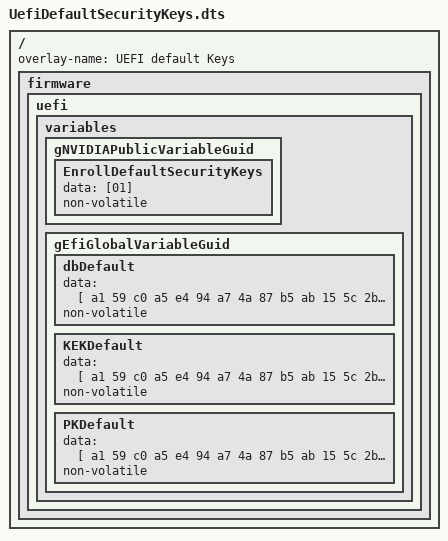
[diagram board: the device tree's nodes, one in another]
/dts-v1/;
/plugin/;
/ {
    overlay-name = "UEFI default Keys";
    fragment@0 {
        target-path = "/";
        board_config {
            sw-modules = "uefi";
        };
        __overlay__ {
            firmware {
                uefi {
                    variables {
                        gNVIDIAPublicVariableGuid {
                            EnrollDefaultSecurityKeys {
                                data = [01];
                                non-volatile;
                            };
                        };
                        gEfiGlobalVariableGuid {
                            dbDefault {
                                data = [
 a1 59 c0 a5 e4 94 a7 4a 87 b5 ab 15 5c 2b f0 72
 45 05 00 00 00 00 00 00 29 05 00 00 67 45 23 01
 ab 89 ef cd 01 23 45 67 89 ab cd ef 30 82 05 15
 30 82 02 fd a0 03 02 01 02 02 14 57 7c a4 0c 8e
 89 bd 30 b7 32 72 16 68 e7 be 2f f2 ab 0b 0f 30
 0d 06 09 2a 86 48 86 f7 0d 01 01 0b 05 00 30 1a
 31 18 30 16 06 03 55 04 03 0c 0f 51 55 41 4c 47
 4f 20 44 42 20 75 65 66 69 31 30 1e 17 0d 32 36
 30 31 30 38 30 36 33 39 30 33 5a 17 0d 33 36 30
 31 30 36 30 36 33 39 30 33 5a 30 1a 31 18 30 16
 06 03 55 04 03 0c 0f 51 55 41 4c 47 4f 20 44 42
 20 75 65 66 69 31 30 82 02 22 30 0d 06 09 2a 86
 48 86 f7 0d 01 01 01 05 00 03 82 02 0f 00 30 82
 02 0a 02 82 02 01 00 f1 f5 b0 6b da cb fa 9c dc
 51 bf 3c e8 96 7a aa e0 8d fe e7 57 ea 79 83 bf
 37 cf ec 4f c1 ca 91 08 57 de ee ae 32 b4 49 be
 80 4b 5f db 68 19 c5 31 b3 a8 4c 23 97 56 7a 4b
 98 7a 26 27 4c 02 b4 20 4f 98 23 fa fa 7a f4 a1
 a3 08 e1 de 35 e8 19 8c 83 12 7e c7 fd 82 a0 79
 41 15 76 a1 21 22 38 b6 3b cc 27 88 2b c1 5f d1
 13 4b ca 03 be d0 67 bc 83 cc a6 5e 26 17 4b f2
 2d c8 c3 53 eb 8b 39 2c fe 3e e5 c0 f3 ce b0 f0
 c8 42 19 b6 09 c5 dc 21 05 1d 9d ee f2 e1 aa 7b
 8f 8e 98 90 2d fb 41 a7 9d 07 ff 31 95 4d d4 59
 a0 89 cf 33 b9 e5 8b 2d 5a 9e 0b 37 46 fa d1 b4
 91 ee 3b ef 3b 04 1c 17 5c f0 cd ad fb 23 60 f5
 47 ea 4c e0 30 f0 1c 8d 01 dd b0 c8 dc 02 fb a4
 50 35 06 72 38 a9 f7 bb 68 82 79 c4 c4 1d 00 c4
 d0 ac 75 34 76 de ad e9 07 e6 63 b0 80 49 25 45
 5a 03 f1 26 50 74 1b a5 f0 47 7c 84 31 51 ca 90
 d0 08 7d 96 61 42 84 71 b9 76 66 a3 2f c1 0b 34
 db 1e cc 6e 17 14 3e 84 a5 27 d4 48 cf 52 a0 7f
 3d 07 32 77 4f 6b 28 13 de e0 b1 71 18 b0 09 e1
 f6 d8 32 9b 73 60 66 08 44 c5 6c b6 1d 63 9e ef
 3e 1d 0a ab ac 57 a1 90 a8 06 39 34 5b 7d 18 b5
 90 cb 73 ee 1b 26 cc da c4 4e 38 58 19 65 67 e7
 fe f7 00 6e 80 ae 2d 9a 71 09 c9 16 24 57 fa d9
 09 03 a5 6a 39 31 06 9d 1a 99 71 f0 d7 cf a6 e5
 40 db 4d 19 a6 19 f0 c3 cf 93 c6 64 48 24 1b fe
 08 09 5f ef a9 ed 24 61 57 23 44 8b 40 c1 77 b2
 a5 e9 f4 8f c0 b0 25 ac d1 88 3e 7b 69 cb 20 58
 28 21 ac 9d 23 d4 c9 fe b1 54 37 ca 64 e2 d2 32
 ee 4f db e2 6b 7d 11 4e 2a 73 9f ec e6 0f 3a 47
 d9 01 1d 2f d1 b1 e6 dd 9c 31 bf fb 8b 17 b7 47
 b0 a1 af 93 9f 8c 8c 11 d9 73 b4 ca bf a0 f9 74
 92 a9 ac 74 d1 19 49 02 03 01 00 01 a3 53 30 51
 30 1d 06 03 55 1d 0e 04 16 04 14 e0 ea da e5 1f
 ef 96 45 55 63 8d 63 1f a7 40 92 a4 90 94 ac 30
 1f 06 03 55 1d 23 04 18 30 16 80 14 e0 ea da e5
 1f ef 96 45 55 63 8d 63 1f a7 40 92 a4 90 94 ac
 30 0f 06 03 55 1d 13 01 01 ff 04 05 30 03 01 01
 ff 30 0d 06 09 2a 86 48 86 f7 0d 01 01 0b 05 00
 03 82 02 01 00 f1 82 a8 df 2c bc 40 50 fe f3 ed
 9f b2 b2 c8 a1 c4 e5 f3 c6 2f 0c 60 60 49 83 79
 34 a2 01 99 ae fa 3b f5 ab 24 4e 55 43 08 7c f1
 bb 25 2d 77 d7 02 b8 38 c4 85 a0 63 84 e5 9c bf
 2c 3c a6 82 aa b4 b6 b5 03 35 e7 f5 dc 87 76 52
 d4 4f 77 0d f8 a0 3c d9 5a c2 88 1c be a5 cf 2f
 7c 34 01 b9 dc 08 6e b3 3a 3c 32 1e b3 6f 31 a5
 1d 24 c4 02 b0 2b 0f 6f a1 45 33 6e 7e 20 67 3d
 82 2f 06 3a 1b 28 c0 11 c6 e7 82 b3 02 cc a6 69
 53 5f ef 82 a3 45 af d0 0c 04 c6 0b cc 7c 2e 5f
 8b 82 33 a8 d4 58 d7 2f 3d 99 3f d8 88 91 78 53
 f2 56 60 23 27 56 fe ee 5b ca b9 31 d0 ba ab 9d
 eb c8 46 71 56 ff 83 1d d2 1b de 78 08 ef c4 e5
 b3 33 c5 f3 88 10 d9 30 b6 ed ee ae 59 f0 6a e0
 da 8a be 82 67 b1 86 c4 fe cd 1b 80 3f 83 a1 67
 e0 af ec 8e 4c ed 7b db 49 9e f4 b2 6f 05 90 03
 87 eb 99 25 10 50 95 e8 69 34 0d 62 ee aa 4c 24
 bc f2 ef 3d 57 76 b2 b9 b7 8a 82 6f f5 fe ac c6
 5e b2 c1 f5 09 f8 95 d3 b3 5e f6 da a7 56 cb 78
 10 e4 c3 2f 3d 96 52 43 3f e9 c3 24 0c 40 a6 71
 2a 06 31 c6 2e f6 08 b5 49 7b 1e 1a e0 06 d0 df
 26 30 cf 27 14 bc ea ad 3c 19 84 7a 6f 2e d6 92
 8c 41 90 8c 05 14 bc fc 24 76 f1 c0 96 26 50 be
 1d 74 a9 da ef 7e f2 db 8c 6d eb 7a bc ba 94 86
 f0 b8 a0 26 79 bf 70 bb 86 2a ea 43 56 2a 07 b5
 42 f9 e9 46 35 95 75 dc a2 eb a9 11 c1 f6 59 a2
 77 6e d3 3f 97 fc 46 c3 0b 03 6f 0e 64 b3 9a 2b
 8e 71 ca 34 f3 61 be f4 f6 86 78 5a 9e fa d6 9f
 16 68 a5 ce e8 30 7c db f3 58 96 a6 96 96 92 6d
 13 7b 58 40 af 14 a9 ac d3 d1 9d 21 34 1d b8 f7
 f9 3f 2a 6c e9 fb b7 3b 1d 86 dd c2 82 ce 2d 55
 b5 ce 28 2f d1 b9 a0 ef d6 52 3d e5 94 92 da 01
 6e 58 a5 64 e3 a1 59 c0 a5 e4 94 a7 4a 87 b5 ab
 15 5c 2b f0 72 45 05 00 00 00 00 00 00 29 05 00
 00 67 45 23 01 ab 89 ef cd 01 23 45 67 89 ab cd
 ef 30 82 05 15 30 82 02 fd a0 03 02 01 02 02 14
 2d 39 bd b9 61 43 fa 52 8c 0d 6c fe 65 6d 98 f5
 7c 57 fe 47 30 0d 06 09 2a 86 48 86 f7 0d 01 01
 0b 05 00 30 1a 31 18 30 16 06 03 55 04 03 0c 0f
 51 55 41 4c 47 4f 20 44 42 20 75 65 66 69 32 30
 1e 17 0d 32 36 30 31 30 38 30 36 33 39 30 33 5a
 17 0d 33 36 30 31 30 36 30 36 33 39 30 33 5a 30
 1a 31 18 30 16 06 03 55 04 03 0c 0f 51 55 41 4c
 47 4f 20 44 42 20 75 65 66 69 32 30 82 02 22 30
 0d 06 09 2a 86 48 86 f7 0d 01 01 01 05 00 03 82
 02 0f 00 30 82 02 0a 02 82 02 01 00 a6 04 c8 e1
 49 a4 44 9b ba 8c cd 31 cc 4d 05 40 37 dc ca 71
 2c 27 bc b2 71 70 b4 ad cd 0e e7 bd 8c a1 3b 45
 c3 e0 ee 68 19 a1 71 12 0f e3 35 de b7 71 a4 10
 f1 b4 d7 7e 1e 21 16 a6 bf ff a9 d3 33 97 c6 3b
 c9 c3 2e 2a 65 18 b4 9c 8b 57 8d b0 16 46 dd d4
 35 28 57 9c dd cb 71 43 1f 5a 30 eb 76 29 6c c5
 58 7e 59 a0 6a 9e ed f2 42 86 bf fd c2 b6 2a 23
 fa 8e a5 ec 7a 8b 4e 79 ee fe ce 7c cf 9e 37 40
 64 e9 97 43 a0 67 28 38 cd 8e 57 43 c2 e0 fa 1a
 03 b1 ff 1c 95 20 50 59 bf d0 9b 8c c5 99 57 dc
 fb 2a e5 86 25 b8 27 67 c5 05 c6 0d 90 15 95 40
 44 87 c0 d2 20 0d e4 cf f8 56 d4 9a 67 a8 1a a0
 33 18 c0 34 cb 9f 16 6e 75 b1 12 93 ea 8f 0b 0c
 71 41 2f 75 9b 73 e7 a5 36 a7 37 cd 68 32 fa 39
 34 dd 9e e8 6a 85 6f 0e ee d0 63 54 2a 0e 86 a0
 a4 b4 5a 82 cd e5 4d 67 5a 81 03 b9 8e 68 82 92
 fd 72 88 fb de 02 90 a1 6f 80 3a 12 1f 73 23 31
 b0 d1 b4 15 99 98 78 c6 0e e3 46 22 c2 49 cc 37
 76 bc f8 6d ce 75 f2 ac c3 f4 c1 75 49 08 28 3f
 93 05 ed 2c 60 e0 6f b8 02 ff 96 a1 2e 35 70 ee
 db 08 3d f6 61 1f ea 23 1c f8 eb b9 e2 30 f9 0d
 8d 9e 14 7a 04 b3 29 86 e8 41 ff e2 de 42 d2 1d
 74 27 64 67 de 10 74 0e 00 3d b8 33 31 bb 83 46
 88 ef fb 6a 74 44 22 5a 6f e1 a3 e8 71 3b 88 76
 0a 07 2a 0c 4e 8e e1 56 90 b1 73 e1 e7 01 d4 bb
 89 3c 53 63 4b c5 26 d9 9f b7 f3 64 df 03 59 5f
 4e cd 6b 8b fa 75 c5 09 ba d7 a6 c0 4e 49 6a 69
 15 55 4e 20 60 23 49 0f 1f 2b cb 1d 53 e9 3d c6
 c1 46 f8 80 c4 61 b7 41 ca d1 ff d6 d8 a1 93 b6
 67 4b dc d2 a6 aa 25 d0 87 bf 2a 8a 10 69 49 d7
 ac b8 9c cb d7 f8 70 d8 57 02 c4 ee 67 a2 17 00
 6a 64 28 1a 19 c5 37 03 22 a0 fc 25 02 03 01 00
 01 a3 53 30 51 30 1d 06 03 55 1d 0e 04 16 04 14
 a4 7a db 9c 31 f1 d2 b2 47 3f bf 2d 48 3b 14 45
 f0 db f8 46 30 1f 06 03 55 1d 23 04 18 30 16 80
 14 a4 7a db 9c 31 f1 d2 b2 47 3f bf 2d 48 3b 14
 45 f0 db f8 46 30 0f 06 03 55 1d 13 01 01 ff 04
 05 30 03 01 01 ff 30 0d 06 09 2a 86 48 86 f7 0d
 01 01 0b 05 00 03 82 02 01 00 61 85 cd c1 08 62
 fd 1f b8 13 ef bb d7 e8 ac 0c 1c 42 28 b4 12 9a
 45 e2 33 a6 5f 9c 1f a5 b3 fc 89 19 2b 02 28 52
 2d bb bf bb 27 cc cb b0 ee 19 bf 40 8e 32 10 3e
 ea 12 3b c9 3f cb 37 63 80 0d be 5e a6 d6 30 d7
 72 96 84 7a 96 5b 13 63 ee fd ee 35 1f 83 32 39
 af 8b 3b f8 01 80 a5 d5 2b 29 d1 b4 38 bf 03 4b
 82 1d e1 28 a7 0e d0 0b ef 7c 2d e0 58 4f 9a 05
 97 13 2b ee 69 c0 d0 58 aa 62 66 d0 81 b4 96 d9
 0e 35 80 d1 79 7c 4d dc 25 07 6c 9f b3 dc 9c 63
 60 80 46 8a a2 cf 32 4b ed 55 d3 ee 0c a2 c3 50
 7e c7 58 c7 e7 f4 7e f5 2f cc 4b 54 0d fb 8b 45
 81 61 41 bf b2 f0 70 5b b5 e0 f2 65 5c ad a6 3f
 2e 56 d6 42 80 a8 15 bd 4e 0a 16 c9 7a b7 cc 08
 05 ed b9 f3 80 ae da 09 2f 3a 2f 80 f4 6e c5 e9
 ed 9e 3a aa fd ff 6c 4a 6b ac 1e 18 6c e9 14 1f
 f9 95 2d ae 9d 45 4a 76 4c eb 88 1e 25 96 e2 a9
 a0 22 f1 9f 32 00 ce 7a 81 82 ad 9a 41 85 8a 4e
 2b 90 cf 4b 8c b6 b7 37 fe 34 15 06 36 9d 77 d6
 7a 14 56 f6 86 f5 00 9f bd 27 17 c0 e3 1f 76 3e
 7e 88 5a 14 48 39 ab 5c c4 d4 86 ad 18 35 cb c2
 88 0d d0 9f cb 6e aa 2f ac 12 18 cb d9 46 0d 97
 af ee 82 bf 72 d4 bd a1 91 f6 09 7b ce 24 35 7d
 dc bb 45 d0 59 a0 d9 a1 b0 07 9a 75 0f cd f7 74
 90 43 8c cd 2e 3c 83 8a ef fe 7f a6 8d 4b 29 61
 03 c3 d4 8b 47 ee 1a 5f 80 67 7c e5 55 8c f2 0d
 4b 57 89 71 b0 3d 0a 60 be 29 eb b8 de 22 e6 b2
 2a ba 23 62 16 68 9a b2 aa e9 a5 2f 90 fa c6 fc
 b1 17 b5 74 45 88 e0 31 60 b4 53 9b 21 f2 02 77
 5c e5 9c 2b 6c 6f 39 3b 39 af 3b 06 d2 55 79 3c
 c5 40 1e c9 30 c2 dd aa 0f 90 61 cd 41 08 51 57
 b3 a5 f6 b6 a7 9c 76 2b a0 75 54 6d bf 1d 91 86
 bd 75 1b 45 4a 78 0c 2d 9a 17 a1 59 c0 a5 e4 94
 a7 4a 87 b5 ab 15 5c 2b f0 72 47 05 00 00 00 00
 00 00 2b 05 00 00 67 45 23 01 ab 89 ef cd 01 23
 45 67 89 ab cd ef 30 82 05 17 30 82 02 ff a0 03
 02 01 02 02 14 3a a1 4c 52 ef 5b 66 79 db 08 af
 a8 fd a9 98 36 1e 8b 27 1b 30 0d 06 09 2a 86 48
 86 f7 0d 01 01 0b 05 00 30 1b 31 19 30 17 06 03
 55 04 03 0c 10 51 55 41 4c 47 4f 20 44 42 20 6b
 65 72 6e 65 6c 30 1e 17 0d 32 36 30 31 30 38 30
 36 33 39 30 34 5a 17 0d 33 36 30 31 30 36 30 36
 33 39 30 34 5a 30 1b 31 19 30 17 06 03 55 04 03
 0c 10 51 55 41 4c 47 4f 20 44 42 20 6b 65 72 6e
 65 6c 30 82 02 22 30 0d 06 09 2a 86 48 86 f7 0d
 01 01 01 05 00 03 82 02 0f 00 30 82 02 0a 02 82
 02 01 00 e4 45 9e a3 9c 46 49 d7 e5 48 5d c8 35
 2d 9d 8b 85 e5 45 58 fb 23 9a 5c 55 db b1 03 45
 22 7f 90 a0 62 fa d1 d7 b4 6e 34 3f 7e 9f 89 44
 0f 47 de b4 bd 5b fd b8 63 6e 9a e8 3c f4 b1 fd
 3d 1e 08 72 c4 ee b8 e0 53 fc 23 c4 3e 96 40 d4
 8d cb 81 e1 b8 c8 28 80 e1 d1 51 8b 43 c2 88 f3
 b2 7c 56 47 22 c6 e6 49 65 cd 66 bf 7c 46 b6 4f
 f6 76 03 75 45 35 15 95 86 e8 92 ed 6c 0c 42 1b
 2a 12 e7 4e b0 cf 16 01 b5 14 fe 0f 7c 97 cd e3
 31 20 19 03 ed 33 46 c2 e6 d6 52 2e 78 a6 03 97
 a4 4b a8 9e 8a 2b 92 a9 62 b8 a3 dd e7 55 96 2e
 1a a5 07 3b 95 ae 5a 51 87 7e b5 e7 1a 08 c2 ae
 91 03 b7 d3 63 b9 22 ab 17 3f a7 16 ab 5e de bf
 33 a3 c5 19 ba 1d 64 f7 0c 28 4a 0e d9 74 57 93
 94 df 7a 05 ad b7 ca c5 ef 7a 0f 99 a2 d1 10 92
 ec ee 0d f7 3a f0 27 18 b6 9a f7 01 99 33 b6 b4
 62 fc 9d a8 c2 f4 b6 d8 52 67 5d b7 35 69 c2 ef
 55 d6 f5 c9 3b 76 e8 ab 40 9e 53 2b c7 5e 7c ab
 a2 cd 2f 5d ab a6 ab fb 30 8d 42 2c 4d 5b cb 08
 2b 8c f5 48 ab a7 ac 89 12 4c 31 c5 b6 de 7c 55
 9f ca aa b8 03 4a 30 f5 4d 58 dc 2f 3c f1 ca b8
 44 9e 77 89 1c 20 b7 d9 d8 7a d4 0e ab 91 73 ef
 18 7e 80 71 7e 83 cd 01 06 6a 62 49 71 59 51 76
 b0 13 67 6b a5 18 db 68 db e5 18 db a0 4b c5 2d
 66 9e 44 9f 85 80 cc 5f cd 48 e2 cf 34 a2 24 47
 54 d1 54 8f 89 97 16 34 bb 3a b2 7b 97 b2 27 f7
 9a 37 dd a4 33 65 e9 75 ec b7 8d fd a1 b8 dd 23
 2b 46 8b 23 87 8d 04 c9 44 aa 8b 46 9c 88 23 ba
 58 d0 df 87 da a6 ba 44 be 7f 98 e9 be a2 5c 4f
 dc 08 02 02 03 4f 51 2f 5a b3 25 9c 67 ad 7b 5c
 d5 4c f8 14 92 8d e9 e7 a5 de bb 99 61 18 82 bc
 7a f1 7f 3b ad 8e 93 b6 71 a4 fc be a9 7e c9 25
 31 12 4d 02 03 01 00 01 a3 53 30 51 30 1d 06 03
 55 1d 0e 04 16 04 14 d9 3f 54 3a b1 b3 4a d1 e0
 75 27 05 15 14 99 29 ff 91 58 90 30 1f 06 03 55
 1d 23 04 18 30 16 80 14 d9 3f 54 3a b1 b3 4a d1
 e0 75 27 05 15 14 99 29 ff 91 58 90 30 0f 06 03
 55 1d 13 01 01 ff 04 05 30 03 01 01 ff 30 0d 06
 09 2a 86 48 86 f7 0d 01 01 0b 05 00 03 82 02 01
 00 b7 4d 7d b5 a9 85 09 09 7a 41 73 e4 3a 49 1c
 06 4f 7f b5 76 53 ec 70 51 8a aa 7a 0d c6 5d df
 d5 b0 88 b3 3f 36 94 3c 9c b8 92 5b e1 55 ab 7d
 64 29 7c 38 2c d4 2c 2c f0 9d f6 5d 27 40 f9 3c
 f2 32 33 5b 20 9d 92 5e 9e ac f0 ba 56 a1 23 4e
 41 2c d4 64 64 7a a7 85 45 9d 5c 4d fd a9 23 8a
 83 40 05 fe b7 dc 08 74 8e 45 fb e7 f6 1e e7 0f
 10 bf 47 85 88 77 a3 36 6b 04 fd 18 5c ae 0a 67
 85 3f 4a 2f 6c 4e cb 8b 58 e6 5f ab f2 f3 bf a5
 5d 1f 5b 62 2a fd ed e1 69 43 ff 31 45 ac 10 6c
 d1 ad 1d 19 78 59 b5 06 d9 6c 74 53 9c 2b c3 db
 de 45 6b cd d3 2d 38 c2 53 72 e4 1c 0d bc 7d f3
 a8 13 92 6c 72 a5 2e 3b 37 23 a1 83 ae 0b 2a 58
 86 eb 0c 7c 4d a1 a9 39 54 f9 32 90 af bd b0 69
 f6 43 b5 4e a7 7b 18 65 62 72 39 9a d4 e9 de 42
 5b 3e a3 67 11 e5 a7 04 6e 6a 95 d5 77 e6 f1 14
 f6 eb 93 02 76 a7 41 19 3c cd c0 36 5d 5a 55 19
 0d 19 ff d9 ae 9c 30 c1 19 6a 0b 32 b8 f3 97 d7
 02 9a ce e6 03 b1 19 aa ac f7 d3 ed 78 32 b5 44
 88 f1 bf db 17 0d 0e e6 22 59 44 25 ab b0 ef 25
 46 35 84 42 28 5a ab 43 4f c2 f9 f7 2a a5 8c e5
 ac 8d b4 b9 d6 3b 3a d8 91 b8 87 e3 38 74 27 65
 01 7b 0c f0 ea 08 5f 6c 68 e8 26 f3 4e 28 93 26
 48 b3 95 d5 9a 8e 89 04 de 3c 71 dd 7b 8b 52 56
 11 1a f3 be 20 3b 11 79 ac 46 14 88 dc ba 4f 8b
 81 45 94 04 64 23 d2 d1 ff 0b 95 40 5b f3 4b db
 29 08 f3 a5 2d a7 5a 15 40 74 09 4f 2a 47 96 a0
 1e 06 6f e2 69 d0 7c ed 33 26 0b 0e 5f 69 ff 82
 76 d0 fe 93 09 a7 00 97 0d 3c 72 0c cd f8 c7 9c
 c4 10 96 d8 32 bc a2 e3 20 9a d5 be dd 75 36 4e
 99 d1 8a 29 07 0c 7b f0 80 68 b1 46 c4 44 5f 28
 c3 5c 58 59 7d 57 94 70 0a 5e f5 33 74 b2 4b a5
 58
                                ];
                                non-volatile;
                            };
                            KEKDefault {
                                data = [
 a1 59 c0 a5 e4 94 a7 4a 87 b5 ab 15 5c 2b f0 72
 3b 05 00 00 00 00 00 00 1f 05 00 00 61 df e4 8b
 ca 93 d2 11 aa 0d 00 e0 98 03 2b 8c 30 82 05 0b
 30 82 02 f3 a0 03 02 01 02 02 14 6c 7d ea 5b 1b
 53 ee f4 5f c5 7d b2 9a 0c 18 8c 8e ed ec 41 30
 0d 06 09 2a 86 48 86 f7 0d 01 01 0b 05 00 30 15
 31 13 30 11 06 03 55 04 03 0c 0a 51 55 41 4c 47
 4f 20 4b 45 4b 30 1e 17 0d 32 36 30 31 30 38 30
 36 33 39 30 32 5a 17 0d 33 36 30 31 30 36 30 36
 33 39 30 32 5a 30 15 31 13 30 11 06 03 55 04 03
 0c 0a 51 55 41 4c 47 4f 20 4b 45 4b 30 82 02 22
 30 0d 06 09 2a 86 48 86 f7 0d 01 01 01 05 00 03
 82 02 0f 00 30 82 02 0a 02 82 02 01 00 9d 32 30
 5d 9e 83 ee 02 34 7d a4 0a 2c e4 c2 5f 4f 99 5f
 13 b5 f2 99 7b 65 43 c0 e3 1f b1 a5 3c fa 21 27
 dc bd e9 37 6b ae ed 79 9b 59 f4 c8 05 d1 04 7c
 f9 0a 8b b4 aa a8 57 99 58 03 09 5c fe 08 40 21
 9d 16 c0 ec ce b0 8f 5c 1a 48 7b 11 32 3e a0 61
 04 05 84 65 19 7b 28 3f b0 fc dc ae e8 1b e8 e5
 34 9a a9 e4 14 df c0 33 e5 79 c2 db 27 4d a9 72
 87 80 d3 46 9b 64 27 c7 61 55 e5 76 04 e9 d6 b6
 3c 74 cb 8b e2 b3 8b 94 85 3e 3f fd 27 42 ec 65
 b9 33 34 fa ad 21 7d 88 77 e3 70 d6 b0 fc 5d 9c
 4a 8e c4 6b b1 bc 35 97 24 6c b2 3f 21 f3 a6 1a
 3f 7e c1 2d f5 a7 74 48 e9 57 2d 24 ca 9b 59 d0
 64 2c 02 df f9 ec b0 af ef 00 58 71 41 e5 4f 8f
 30 64 6c a4 41 11 4f 36 0e 7e 79 01 e9 9a 1e 4c
 f8 4e e1 87 80 eb 78 5d 0a f0 68 4d bd bb 4b a9
 dc 2c e9 b9 b0 39 29 d3 dc 7b bf 77 b5 9a c7 f6
 19 fe 4c e4 ef 26 f7 fd 2d 51 73 cb b0 94 56 1f
 f0 7a df 3b a5 1e ae cd c9 38 32 06 19 bd d6 3e
 2f e6 71 25 a2 48 c3 32 6d fa c9 ce 0a ef 00 2a
 3a 0e fa 13 1d 36 b5 d8 e1 d5 a2 1f 24 95 4d d8
 b8 2e 5b 8c 5a b9 56 04 25 ea dc 21 b5 6c 97 84
 16 ce 28 2c db a6 25 80 bb 8a 3d 52 36 25 8d 72
 87 f7 01 24 6a 00 c9 d3 91 7c 2b 10 0d 51 0f 24
 37 5f 08 63 dd 48 2a e6 68 28 e1 8c 31 e1 1f f9
 58 38 08 34 55 90 58 7b 51 0b 35 a8 62 b3 23 56
 72 89 68 ee 69 7f b1 88 51 aa 9a f4 6b c0 e2 6f
 20 ca 71 25 05 57 eb bd e1 41 14 46 2d eb 4f 16
 8c 88 5d 0a 6f 86 41 fc 32 4b 4f 53 9b 5a 23 66
 1f 8c ea 7f 92 0a ca 28 d9 c7 e0 0f d4 05 df a5
 93 9a 3d 5e 96 ca 80 b6 d1 26 19 19 7a a9 a6 92
 7b ae 73 74 cf 05 45 ed ea ad f0 6e 29 06 4e e7
 18 4f 84 c8 f7 d1 a9 e1 a6 a6 ec 29 c9 02 03 01
 00 01 a3 53 30 51 30 1d 06 03 55 1d 0e 04 16 04
 14 7f b6 b5 2b 80 31 03 f9 2a 70 61 e6 6d f8 6e
 03 6d 90 62 da 30 1f 06 03 55 1d 23 04 18 30 16
 80 14 7f b6 b5 2b 80 31 03 f9 2a 70 61 e6 6d f8
 6e 03 6d 90 62 da 30 0f 06 03 55 1d 13 01 01 ff
 04 05 30 03 01 01 ff 30 0d 06 09 2a 86 48 86 f7
 0d 01 01 0b 05 00 03 82 02 01 00 79 18 a9 21 5a
 76 93 89 f1 38 a9 44 50 c1 5c 21 53 f4 9c 64 2d
 2d 61 91 0f a2 c8 e5 4a ad 16 22 d1 04 f7 23 16
 a8 50 08 76 8f 7c 8f 18 6a e8 2d 1d c0 e9 a0 c0
 dd 45 f5 62 b7 9c fe 7a 15 cf 68 71 3a ec 87 f0
 a6 1f b9 e0 93 2c be f9 c7 87 d8 35 8f ad 2a dd
 df a5 7f cf 5e 9d aa 5b 04 56 4f b5 f2 d3 05 ec
 12 56 fe 28 41 fe 41 73 f4 b1 4e 41 4c 84 84 0d
 6d f6 23 d2 01 f8 43 46 d0 6c d0 2f 9f be 62 5d
 d5 85 d0 bc d1 3d 71 cd b8 4a 36 c6 1c 6f 96 14
 54 0d b8 d7 53 58 bb 7e 6a f6 9b 06 ee c0 a3 cc
 95 27 d6 4e aa 23 84 0f d6 47 b6 3a 79 70 28 99
 8e 68 a0 37 5b 65 b7 5c cc 68 f4 7b a6 89 2d 5e
 10 ca 47 69 51 4c 6c 86 6f 5a 5b 44 aa 1b 86 03
 cb 95 ef c0 2c 96 ab 93 37 49 b6 a9 06 4b f4 3d
 98 f9 b5 93 8f 59 00 0a bb 34 3a fd cd 1f dc 52
 0f df fc 8d f5 95 21 a9 55 08 73 5a cd 25 0b 02
 f8 14 c7 9b e1 af 62 56 51 10 b1 1a 01 c5 6e f3
 f5 99 58 c0 73 ba 1a 7f 2e 9e 54 a1 eb 7c 40 71
 1c ee 9a dc c2 56 56 d6 4f 0f 70 27 5b bd 8e aa
 14 d2 df 50 57 0e e2 d0 a6 c3 21 54 b3 ac 4b 72
 de 09 45 ab a7 86 81 4e 0b e4 d8 f7 89 16 57 17
 6f f7 e8 74 e3 3a f0 36 bb 45 71 a1 0a 4b 14 38
 73 4f b9 3b 7d d9 76 ec 19 52 b7 ae 05 d9 fc c2
 00 e5 9c 52 d2 d1 73 22 db 49 90 7c 7c b8 eb ba
 b6 fe 66 3b 03 27 d0 48 14 91 72 dc e6 4c b8 61
 3d 3b 82 0c de bc 35 9a de b9 36 ff 3a 98 b1 df
 1b f7 38 2c 1b 6b da 60 d2 4d 62 78 3a a9 2a e1
 8b 2a 93 d4 64 b2 26 69 4b 8e de 8d f5 bb 67 5e
 7a b4 3b 7b d2 ac 71 45 68 1d 92 76 16 62 cd 9b
 de c4 1c e0 c6 1d 04 12 47 13 b3 e0 06 2f 1f 28
 da b0 a4 a8 61 7b 5a eb 4f 68 0b 0d 30 11 9f 05
 b0 03 d4 fe 8e 1c 5f ae 8d 1b ca
                                ];
                                non-volatile;
                            };
                            PKDefault {
                                data = [
 a1 59 c0 a5 e4 94 a7 4a 87 b5 ab 15 5c 2b f0 72
 39 05 00 00 00 00 00 00 1d 05 00 00 61 df e4 8b
 ca 93 d2 11 aa 0d 00 e0 98 03 2b 8c 30 82 05 09
 30 82 02 f1 a0 03 02 01 02 02 14 75 de 58 32 4a
 a6 a6 cb 0d 4a a4 60 b6 13 bb 5f 07 94 d3 6d 30
 0d 06 09 2a 86 48 86 f7 0d 01 01 0b 05 00 30 14
 31 12 30 10 06 03 55 04 03 0c 09 51 55 41 4c 47
 4f 20 50 4b 30 1e 17 0d 32 36 30 31 30 38 30 36
 33 39 30 31 5a 17 0d 33 36 30 31 30 36 30 36 33
 39 30 31 5a 30 14 31 12 30 10 06 03 55 04 03 0c
 09 51 55 41 4c 47 4f 20 50 4b 30 82 02 22 30 0d
 06 09 2a 86 48 86 f7 0d 01 01 01 05 00 03 82 02
 0f 00 30 82 02 0a 02 82 02 01 00 9d 45 96 64 96
 56 9c 78 4d ec f9 8c e9 fa c9 a6 1b cd 14 37 1f
 a5 72 4f 7a dd be 54 91 00 c3 ea 0f 3f f8 8f 16
 65 f7 33 cc 55 09 dd e6 6b 78 ec b2 4f 0c 06 6e
 dc e1 22 46 66 ac 91 15 ec a5 1d 6f e5 99 39 3b
 2f 7c 51 b0 bb 4f 2d 9e da 61 45 20 14 c5 ff 17
 86 43 84 aa 5f 82 b1 98 77 06 d2 41 ef b2 3d b1
 53 fe 4e 45 f9 1c 6c 60 00 e0 5e 5e 63 76 1f de
 e1 de fe fa 79 72 eb ff e7 19 77 75 31 1f 2f be
 88 ea 7f 78 60 a0 60 a0 f9 79 fd b8 58 9c f7 ab
 90 57 4f b7 f4 a4 8a 50 d0 d1 eb 3d a7 20 84 69
 4d d1 7e 10 ac 0a 66 22 bf 6c fe 04 62 6f c8 4d
 8a 5b 04 4e 36 a8 c8 b5 e5 7c 63 ff 33 44 20 c4
 6f 82 7d 9c 2d d1 4c 72 8f 49 b0 c7 88 ae 8f f4
 55 b8 73 9f 3b d4 9c 65 36 dd 50 44 93 6f f9 0b
 63 4e e5 ee 57 76 1b 7a 2b 4e 84 c0 6f f5 cf e1
 3a 1f 90 6b c9 6d 98 b5 a9 65 cf e8 7c be f7 87
 c1 91 46 fa 4a 40 ef 27 11 05 68 6c e4 2a 3e bd
 00 f6 a5 48 10 61 dc c0 8f e7 1a 56 fe 84 bf 57
 47 73 40 af 8d 9f d8 80 e9 b2 be 82 b9 ec 82 dc
 6a cf f6 4f 7c b9 08 14 0d f6 4a ca 4f 61 7c b0
 f8 c8 ce 96 8c 99 59 33 e8 19 6b c4 8c d9 ef 69
 b6 cb 04 1f 11 9b e8 e1 08 81 50 6f 28 b4 ed 8b
 40 6a 61 69 bc 26 e8 47 c2 7e 0f f3 af 93 a6 3c
 3e c7 6e 3b 49 1c 20 48 3e 92 5d e9 a9 d6 0f da
 21 a8 07 3a 34 bf e6 fd 9e 09 85 a1 8b 00 82 31
 1e 6c f6 c2 d2 75 f9 c5 f5 a1 bc 17 35 90 6c cc
 7a 55 93 f5 ec a6 59 1c d3 8a 20 9e d4 19 38 07
 35 cc 70 c3 91 ea 9e 13 ea 83 8a 8a b9 a3 bf fb
 10 7b 61 02 73 87 77 e1 2e 3e 93 65 cc f7 d9 ae
 cd 25 f7 df 61 0c 94 2d d7 b6 30 f0 c2 dc cb f8
 ce 56 1f b0 83 08 7c b5 f1 aa f1 59 7f 1c f6 d8
 c6 ab ff 38 c2 d1 22 ef d1 69 df 02 03 01 00 01
 a3 53 30 51 30 1d 06 03 55 1d 0e 04 16 04 14 76
 93 cc 8a 6a 8c eb 0d 79 8e 74 d2 a5 5e cb 07 af
 6a 57 56 30 1f 06 03 55 1d 23 04 18 30 16 80 14
 76 93 cc 8a 6a 8c eb 0d 79 8e 74 d2 a5 5e cb 07
 af 6a 57 56 30 0f 06 03 55 1d 13 01 01 ff 04 05
 30 03 01 01 ff 30 0d 06 09 2a 86 48 86 f7 0d 01
 01 0b 05 00 03 82 02 01 00 4d 80 a8 b4 ca a2 8f
 60 9a 1c 37 a9 de 38 05 af a1 2f 3f 99 fe b0 b8
 23 e2 27 bd 28 04 84 36 b0 93 3d d3 45 b5 4b a4
 47 77 26 a0 fd 2b eb 5a 61 a2 54 59 b2 07 f7 09
 be e3 29 d3 f8 8d e8 42 5d 30 8f 6a ac ca 97 74
 c8 92 5a ea 0e c1 d6 ac e6 ce 3c 44 8f 43 2b 48
 58 06 51 4c dc a9 0d e5 ab 36 9f 4c 10 b2 70 ae
 74 78 ef 76 3b 85 00 eb be d9 34 68 01 92 bc a1
 80 6b fd f9 28 18 71 8d b6 aa 19 fa e3 e1 01 4d
 15 39 8e 3b 05 83 3e 29 d7 a1 bd d9 24 9a 91 89
 2e 32 03 30 af 4d cc 1b 2f 24 25 8d a7 61 a5 e5
 cd 42 b4 31 a2 bb c3 56 0f 02 e5 ec 03 89 8d df
 48 05 9b 2d bd 98 7d 72 c7 db 5a f7 29 08 e2 c4
 16 56 30 8d b1 82 b6 d8 9b 0a 99 7f e9 52 32 85
 53 22 f6 7c 21 f4 c2 95 ad e5 4f bf 22 63 9c dd
 79 05 b2 59 09 8d 4f f1 23 1b 5d 33 14 39 04 ff
 4e d7 0c d6 1c 13 a0 26 7a 1b a2 fd cd c6 8e 0c
 9f c4 37 a9 e5 21 81 90 4c 43 a0 6d 08 77 a0 7b
 cb 9d c0 0d b9 04 95 42 c9 b2 9f c0 93 e6 45 3e
 87 f3 5d d8 9d 2a 4e ca 61 01 29 f9 9f e0 55 e6
 f1 ea 45 2f fe 7f 5e 0b 53 7b 80 4c 47 2e 64 cf
 31 5e f0 e8 b0 52 e6 fd c5 f5 31 36 33 2a c6 3c
 11 75 e2 cc 4d 58 19 3f 2b 94 b4 92 c8 c0 bc 31
 77 ae cf 7b 64 81 82 63 de 30 82 df 1e 77 a1 f5
 a4 c0 5d c9 1a d4 0e 97 4a 49 28 69 11 6f 11 59
 b4 dc cd 68 c0 8c 0c 90 76 59 8d d1 1e 5d 6b 71
 73 67 b7 88 9e 49 a9 63 35 61 e8 29 74 07 66 73
 f4 b9 67 8c 07 6f 34 a4 16 9c 54 02 85 bc 11 71
 2d 50 54 b0 ff 79 64 9c f1 d6 79 1f 64 0f 2f 15
 49 d1 b0 f7 ac 2c ba 38 af ef be e0 25 1a 6c 55
 d7 0e ca f7 26 ae 68 b9 fe 93 20 ab d3 99 6d bc
 ed da 60 9a 79 e5 e4 24 d9 ee ef 1e b7 9f 0e 9e
 65 8e 7d 52 fc a9 c0 84 42
                                ];
                                non-volatile;
                            };
                        };
                    };
                };
            };
        };
    };
};
